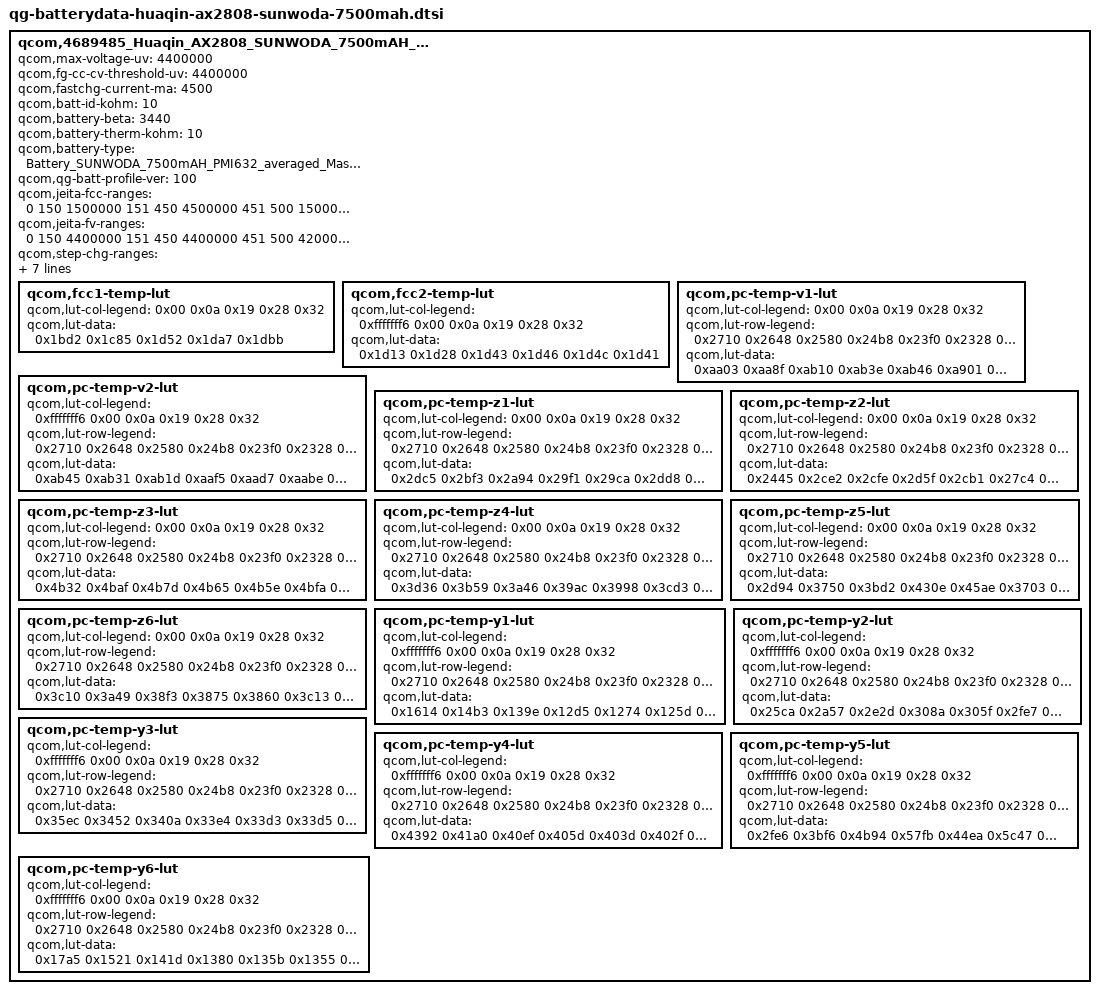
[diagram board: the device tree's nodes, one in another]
qcom,4689485_Huaqin_AX2808_SUNWODA_7500mAH_PMI632 {
	qcom,max-voltage-uv = <4400000>;
	qcom,fg-cc-cv-threshold-uv = <4400000>;
	qcom,fastchg-current-ma = <4500>;
	qcom,batt-id-kohm = <10>;
	qcom,battery-beta = <3440>;
	qcom,battery-therm-kohm = <10>;
	qcom,battery-type = "Battery_SUNWODA_7500mAH_PMI632_averaged_MasterSlave_Jul21th2020";
	qcom,qg-batt-profile-ver = <100>;
	qcom,jeita-fcc-ranges = <0 150 1500000 151 450 4500000 451 500 1500000>;
	qcom,jeita-fv-ranges = <0 150 4400000 151 450 4400000 451 500 4200000>;
	qcom,step-chg-ranges = <3600000 3800000 4500000 3800001 4300000 4500000 4300001 4400000 2500000>;
	qcom,ocv-based-step-chg;
	qcom,jeita-soft-thresholds = <9600 4016>;
	qcom,jeita-hard-thresholds = <22733 8376>;
	qcom,jeita-soft-hys-thresholds = <20318 10563>;
	qcom,jeita-soft-fcc-ua = <4500000 4500000>;
	qcom,jeita-soft-fv-uv = <4400000 4400000>;

	qcom,fcc1-temp-lut {
		qcom,lut-col-legend = <0x00 0x0a 0x19 0x28 0x32>;
		qcom,lut-data = <0x1bd2 0x1c85 0x1d52 0x1da7 0x1dbb>;
	};

	qcom,fcc2-temp-lut {
		qcom,lut-col-legend = <0xfffffff6 0x00 0x0a 0x19 0x28 0x32>;
		qcom,lut-data = <0x1d13 0x1d28 0x1d43 0x1d46 0x1d4c 0x1d41>;
	};

	qcom,pc-temp-v1-lut {
		qcom,lut-col-legend = <0x00 0x0a 0x19 0x28 0x32>;
		qcom,lut-row-legend = <0x2710 0x2648 0x2580 0x24b8 0x23f0 0x2328 0x2260 0x2198 0x20d0 0x2008 0x1f40 0x1e78 0x1db0 0x1ce8 0x1c20 0x1b58 0x1a90 0x19c8 0x1900 0x1838 0x1770 0x16a8 0x15e0 0x1518 0x1450 0x1388 0x12c0 0x11f8 0x1130 0x1068 0xfa0 0xed8 0xe10 0xd48 0xc80 0xbb8 0xaf0 0xa28 0x960 0x898 0x7d0 0x708 0x640 0x578 0x4b0 0x3e8 0x384 0x320 0x2bc 0x258 0x1f4 0x190 0x12c 0xc8 0x64 0x00>;
		qcom,lut-data = <0xaa03 0xaa8f 0xab10 0xab3e 0xab46 0xa901 0xa9ad 0xaa45 0xaa83 0xaa8e 0xa806 0xa8c5 0xa96b 0xa9b6 0xa9c5 0xa715 0xa7d9 0xa88b 0xa8e0 0xa8f2 0xa62c 0xa6ef 0xa7a2 0xa800 0xa815 0xa549 0xa606 0xa6b6 0xa716 0xa730 0xa467 0xa520 0xa5cd 0xa62d 0xa648 0xa389 0xa43c 0xa4e3 0xa541 0xa55e 0xa2b0 0xa35b 0xa3fc 0xa456 0xa475 0xa1dd 0xa27f 0xa316 0xa36d 0xa38f 0xa10e 0xa1aa 0xa234 0xa287 0xa2ac 0xa046 0xa0da 0xa159 0xa1a7 0xa1cc 0x9f85 0xa013 0xa082 0xa0cc 0xa0ed 0x9ec7 0x9f53 0x9fb3 0x9ff9 0xa016 0x9e06 0x9e96 0x9eeb 0x9f2b 0x9f46 0x9d47 0x9dda 0x9e2a 0x9e64 0x9e7e 0x9c9a 0x9d21 0x9d73 0x9da6 0x9dbe 0x9c00 0x9c78 0x9cc3 0x9cf2 0x9d05 0x9b72 0x9be0 0x9c1b 0x9c42 0x9c52 0x9ae9 0x9b49 0x9b81 0x9ba2 0x9bae 0x9a67 0x9aa1 0x9ad4 0x9afb 0x9b08 0x99e4 0x99ee 0x99e1 0x9a1c 0x9a39 0x995b 0x9931 0x98d6 0x98fd 0x9936 0x98d0 0x9851 0x981f 0x982d 0x9865 0x9847 0x978b 0x979d 0x97ba 0x97e3 0x97b8 0x9720 0x9736 0x975f 0x9777 0x9737 0x96d9 0x96e7 0x96ff 0x970a 0x96d9 0x969f 0x96a5 0x96a2 0x969f 0x968e 0x966f 0x9661 0x9648 0x963e 0x9653 0x9645 0x961b 0x95f0 0x95e4 0x9629 0x9619 0x95da 0x959f 0x9592 0x9606 0x95ee 0x959c 0x955a 0x9549 0x95e4 0x95c3 0x9562 0x951e 0x9507 0x95c4 0x9599 0x952f 0x94e5 0x94c8 0x95a4 0x9570 0x9502 0x94b1 0x948e 0x9583 0x9548 0x94d7 0x947d 0x9455 0x9561 0x9523 0x94b0 0x9449 0x9415 0x9534 0x94f6 0x9488 0x9413 0x93d1 0x94e8 0x94ab 0x944b 0x93ce 0x9384 0x9487 0x9442 0x93e7 0x9372 0x932b 0x9421 0x93ce 0x9374 0x9308 0x92c5 0x93ac 0x934e 0x92fc 0x9294 0x9250 0x9329 0x92bd 0x9275 0x9211 0x91c9 0x9292 0x920f 0x91d0 0x9173 0x912b 0x91f1 0x9180 0x9140 0x90e8 0x90a5 0x9186 0x912b 0x90e6 0x9099 0x9057 0x915e 0x910c 0x90d2 0x9083 0x9045 0x913c 0x90fa 0x90c2 0x9072 0x9035 0x9116 0x90ee 0x90ab 0x9061 0x9021 0x90d3 0x90b2 0x9076 0x9028 0x8fe2 0x8ff7 0x8fc7 0x8f80 0x8f21 0x8ecb 0x8e30 0x8e05 0x8dd0 0x8d70 0x8d19 0x8bea 0x8bc3 0x8b9b 0x8b3a 0x8ae4 0x88d5 0x88b3 0x889b 0x8839 0x87e7 0x83e6 0x83e7 0x83fc 0x839c 0x834f 0x7530 0x7530 0x7530 0x7530 0x7530>;
	};

	qcom,pc-temp-v2-lut {
		qcom,lut-col-legend = <0xfffffff6 0x00 0x0a 0x19 0x28 0x32>;
		qcom,lut-row-legend = <0x2710 0x2648 0x2580 0x24b8 0x23f0 0x2328 0x2260 0x2198 0x20d0 0x2008 0x1f40 0x1e78 0x1db0 0x1ce8 0x1c20 0x1b58 0x1a90 0x19c8 0x1900 0x1838 0x1770 0x16a8 0x15e0 0x1518 0x1450 0x1388 0x12c0 0x11f8 0x1130 0x1068 0xfa0 0xed8 0xe10 0xd48 0xc80 0xbb8 0xaf0 0xa28 0x960 0x898 0x7d0 0x708 0x640 0x578 0x4b0 0x3e8 0x384 0x320 0x2bc 0x258 0x1f4 0x190 0x12c 0xc8 0x64 0x00>;
		qcom,lut-data = <0xab45 0xab31 0xab1d 0xaaf5 0xaad7 0xaabe 0xa9a7 0xa9de 0xaa06 0xa9f0 0xa9e1 0xa9d1 0xa828 0xa8a6 0xa8fa 0xa8f3 0xa8ef 0xa8e7 0xa6c9 0xa78b 0xa7fb 0xa800 0xa803 0xa7ff 0xa588 0xa68f 0xa709 0xa716 0xa71d 0xa71b 0xa45e 0xa597 0xa61a 0xa62d 0xa636 0xa636 0xa32d 0xa498 0xa528 0xa543 0xa54d 0xa54e 0xa21a 0xa399 0xa439 0xa459 0xa463 0xa465 0xa183 0xa291 0xa34e 0xa373 0xa37f 0xa380 0xa13c 0xa173 0xa266 0xa28f 0xa29d 0xa29e 0xa0de 0xa087 0xa183 0xa1af 0xa1be 0xa1be 0x9f91 0x9ffb 0xa0a3 0xa0d6 0xa0e4 0xa0e5 0x9d8f 0x9f88 0x9fc9 0xa001 0xa00c 0xa010 0x9c54 0x9ed8 0x9f01 0x9f32 0x9f3c 0x9f42 0x9ba2 0x9dc6 0x9e49 0x9e66 0x9e71 0x9e77 0x9afb 0x9caf 0x9d90 0x9da3 0x9dae 0x9db4 0x9a2e 0x9bcd 0x9cd0 0x9cea 0x9cf4 0x9cf9 0x9955 0x9afb 0x9c0b 0x9c38 0x9c42 0x9c44 0x987d 0x9a21 0x9b30 0x9b85 0x9b93 0x9b95 0x9794 0x993e 0x9a37 0x9ad4 0x9aec 0x9af0 0x96d4 0x9860 0x994d 0x9a17 0x9a36 0x9a3e 0x9661 0x9788 0x9882 0x992d 0x994d 0x9958 0x960a 0x96bb 0x97cb 0x983b 0x985b 0x9865 0x95bc 0x9616 0x972d 0x978b 0x97ab 0x97b5 0x9576 0x958b 0x96a4 0x9706 0x9725 0x9731 0x9537 0x9520 0x9628 0x9692 0x96b0 0x96be 0x94fb 0x94d9 0x95b5 0x9627 0x9647 0x9652 0x94c2 0x94a2 0x954c 0x95c5 0x95e8 0x95ef 0x9489 0x946e 0x94e7 0x956b 0x958f 0x9594 0x944f 0x943f 0x9483 0x9518 0x953a 0x953f 0x9416 0x9411 0x9432 0x94cb 0x94ed 0x94f2 0x93d9 0x93e3 0x93fa 0x9482 0x94a8 0x94ab 0x939b 0x93b5 0x93cd 0x943d 0x9467 0x9469 0x935b 0x9382 0x93a5 0x93fa 0x9422 0x9421 0x9319 0x934b 0x9382 0x93bb 0x93db 0x93d4 0x92d4 0x9310 0x935c 0x937b 0x938d 0x937e 0x928d 0x92ce 0x9332 0x9338 0x932f 0x9315 0x9242 0x9287 0x9302 0x92f4 0x92cb 0x92a1 0x91f4 0x9238 0x92c0 0x92ac 0x9273 0x923f 0x91a3 0x91df 0x925f 0x9261 0x9227 0x91ec 0x9150 0x917f 0x91ef 0x920d 0x91d4 0x9196 0x9101 0x911b 0x9176 0x91a3 0x916e 0x912f 0x90b2 0x90b0 0x90f3 0x9129 0x90f9 0x90bb 0x9063 0x9039 0x906c 0x9096 0x9066 0x902a 0x9010 0x8fbe 0x8fed 0x902e 0x9004 0x8fd0 0x8fb5 0x8f4d 0x8f89 0x9002 0x8fe7 0x8fb0 0x8f7e 0x8f1c 0x8f5f 0x8fed 0x8fd9 0x8fa6 0x8f40 0x8ee7 0x8f38 0x8fda 0x8fc4 0x8f93 0x8ef9 0x8eaf 0x8efe 0x8fb4 0x8fa6 0x8f70 0x8e90 0x8e62 0x8e9b 0x8f62 0x8f47 0x8f0a 0x8de6 0x8dbd 0x8dbb 0x8e41 0x8e20 0x8dcf 0x8ca2 0x8c59 0x8c27 0x8c64 0x8c47 0x8bf3 0x8a90 0x8a19 0x89d2 0x89fd 0x89db 0x8987 0x8789 0x86e4 0x86b3 0x86ac 0x8689 0x8636 0x82ba 0x81e3 0x81cf 0x819e 0x8182 0x8133 0x77e1 0x72c6 0x725b 0x72e2 0x734d 0x7468>;
	};

	qcom,pc-temp-z1-lut {
		qcom,lut-col-legend = <0x00 0x0a 0x19 0x28 0x32>;
		qcom,lut-row-legend = <0x2710 0x2648 0x2580 0x24b8 0x23f0 0x2328 0x2260 0x2198 0x20d0 0x2008 0x1f40 0x1e78 0x1db0 0x1ce8 0x1c20 0x1b58 0x1a90 0x19c8 0x1900 0x1838 0x1770 0x16a8 0x15e0 0x1518 0x1450 0x1388 0x12c0 0x11f8 0x1130 0x1068 0xfa0 0xed8 0xe10 0xd48 0xc80 0xbb8 0xaf0 0xa28 0x960 0x898 0x7d0 0x708 0x640 0x578 0x4b0 0x3e8 0x384 0x320 0x2bc 0x258 0x1f4 0x190 0x12c 0xc8 0x64 0x00>;
		qcom,lut-data = <0x2dc5 0x2bf3 0x2a94 0x29f1 0x29ca 0x2dd8 0x2c0a 0x2a99 0x29fc 0x29d2 0x2de3 0x2c0c 0x2a9c 0x29fb 0x29d4 0x2de2 0x2c08 0x2a9c 0x29fa 0x29d5 0x2dd5 0x2c05 0x2a97 0x29f9 0x29d5 0x2dc9 0x2bff 0x2a92 0x29f7 0x29d4 0x2dc4 0x2bf8 0x2a8e 0x29f5 0x29d3 0x2dc1 0x2bf6 0x2a8b 0x29f3 0x29d3 0x2dbe 0x2bf7 0x2a8a 0x29f2 0x29d3 0x2dba 0x2bf7 0x2a8b 0x29f1 0x29d3 0x2db6 0x2bf0 0x2a8c 0x29f1 0x29d3 0x2db1 0x2be7 0x2a8b 0x29f0 0x29d2 0x2dab 0x2be3 0x2a89 0x29f0 0x29d2 0x2da8 0x2be1 0x2a88 0x29ef 0x29d2 0x2da9 0x2be0 0x2a87 0x29ef 0x29d2 0x2dac 0x2be1 0x2a87 0x29ef 0x29d2 0x2daa 0x2be3 0x2a87 0x29ef 0x29d2 0x2d9d 0x2be5 0x2a88 0x29f0 0x29d3 0x2d91 0x2be6 0x2a8a 0x29f1 0x29d3 0x2d8e 0x2be6 0x2a8c 0x29f2 0x29d4 0x2d88 0x2be6 0x2a8e 0x29f3 0x29d5 0x2d84 0x2be8 0x2a90 0x29f4 0x29d6 0x2d87 0x2be9 0x2a92 0x29f5 0x29d7 0x2d8d 0x2beb 0x2a94 0x29f7 0x29d8 0x2d8f 0x2bec 0x2a97 0x29f9 0x29da 0x2d90 0x2bec 0x2a9a 0x29fb 0x29db 0x2d92 0x2bec 0x2a9b 0x29fd 0x29dd 0x2d93 0x2bed 0x2a9c 0x2a00 0x29e0 0x2d93 0x2bef 0x2a9d 0x2a02 0x29e2 0x2d91 0x2bf1 0x2aa0 0x2a05 0x29e4 0x2d8f 0x2bf1 0x2aa2 0x2a07 0x29e6 0x2d8d 0x2bf1 0x2aa6 0x2a0a 0x29e7 0x2d8d 0x2bf0 0x2aa9 0x2a0c 0x29e8 0x2d8f 0x2bf2 0x2aaa 0x2a0e 0x29e9 0x2d92 0x2bf5 0x2aab 0x2a10 0x29eb 0x2d97 0x2bf9 0x2aac 0x2a12 0x29ed 0x2d9e 0x2bfc 0x2ab1 0x2a13 0x29ee 0x2da7 0x2c00 0x2ab6 0x2a15 0x29f0 0x2db1 0x2c04 0x2ab8 0x2a17 0x29f1 0x2dbb 0x2c08 0x2ab8 0x2a19 0x29f3 0x2dbd 0x2c0b 0x2ab9 0x2a1a 0x29f5 0x2db8 0x2c0f 0x2abb 0x2a1c 0x29f6 0x2dbc 0x2c10 0x2ac0 0x2a1f 0x29f8 0x2dcd 0x2c0f 0x2ac6 0x2a21 0x29f9 0x2dc8 0x2c12 0x2ac9 0x2a24 0x29fb 0x2db1 0x2c17 0x2ad0 0x2a26 0x29fc 0x2db5 0x2c22 0x2ac9 0x2a26 0x29fb 0x2dc8 0x2c1c 0x2ac8 0x2a26 0x29fc 0x2dc8 0x2c10 0x2ac9 0x2a27 0x29fd 0x2db3 0x2c1f 0x2ad2 0x2a2a 0x29fe 0x2dc5 0x2c24 0x2ad3 0x2a2d 0x2a01 0x2dde 0x2c21 0x2ad8 0x2a31 0x2a05 0x2dc3 0x2c39 0x2ae8 0x2a36 0x2a0a 0x2dd3 0x2c3e 0x2aed 0x2a41 0x2a11 0x2dd3 0x2c3e 0x2aed 0x2a41 0x2a11 0x2dd3 0x2c3e 0x2aed 0x2a41 0x2a11>;
	};

	qcom,pc-temp-z2-lut {
		qcom,lut-col-legend = <0x00 0x0a 0x19 0x28 0x32>;
		qcom,lut-row-legend = <0x2710 0x2648 0x2580 0x24b8 0x23f0 0x2328 0x2260 0x2198 0x20d0 0x2008 0x1f40 0x1e78 0x1db0 0x1ce8 0x1c20 0x1b58 0x1a90 0x19c8 0x1900 0x1838 0x1770 0x16a8 0x15e0 0x1518 0x1450 0x1388 0x12c0 0x11f8 0x1130 0x1068 0xfa0 0xed8 0xe10 0xd48 0xc80 0xbb8 0xaf0 0xa28 0x960 0x898 0x7d0 0x708 0x640 0x578 0x4b0 0x3e8 0x384 0x320 0x2bc 0x258 0x1f4 0x190 0x12c 0xc8 0x64 0x00>;
		qcom,lut-data = <0x2445 0x2ce2 0x2cfe 0x2d5f 0x2cb1 0x27c4 0x2c55 0x2cec 0x2d98 0x2d5e 0x2a3c 0x2c13 0x2d49 0x2e08 0x2e4f 0x2acf 0x2be8 0x2d5a 0x2e38 0x2ef0 0x2abc 0x2bbd 0x2d2f 0x2e23 0x2ec4 0x2aa8 0x2b8d 0x2cf8 0x2def 0x2e32 0x2a9e 0x2b60 0x2cba 0x2dbf 0x2dde 0x2a98 0x2b3b 0x2c7d 0x2d87 0x2dbc 0x2a90 0x2b19 0x2c72 0x2d6a 0x2d94 0x2a85 0x2b08 0x2c82 0x2d7a 0x2d1f 0x2a78 0x2b01 0x2c95 0x2d94 0x2c6f 0x2a6a 0x2afd 0x2ca6 0x2d98 0x2c45 0x2a57 0x2b03 0x2cb8 0x2d91 0x2c62 0x2a43 0x2b2b 0x2cc8 0x2d8b 0x2c76 0x2a2d 0x2b57 0x2cdd 0x2d5b 0x2c76 0x2a16 0x2b75 0x2cf1 0x2d1c 0x2c80 0x2a10 0x2b8f 0x2d04 0x2d0b 0x2c9a 0x2a1f 0x2ba5 0x2d16 0x2ce3 0x2cd3 0x2a3c 0x2bb7 0x2d25 0x2cd0 0x2d0e 0x2a5b 0x2bca 0x2d32 0x2cde 0x2d4b 0x2a83 0x2be6 0x2d46 0x2cf9 0x2d7f 0x2aa4 0x2c09 0x2d99 0x2d78 0x2d81 0x2ab9 0x2c18 0x2e07 0x2ed8 0x2d69 0x2ac9 0x2c18 0x2e0d 0x2f76 0x2d5c 0x2adc 0x2c17 0x2dac 0x2e7b 0x2da7 0x2af3 0x2c1b 0x2d69 0x2d58 0x2e29 0x2b0a 0x2c25 0x2d74 0x2da8 0x2e95 0x2b1e 0x2c2e 0x2d90 0x2ef3 0x2f08 0x2b2e 0x2c35 0x2db3 0x2f7a 0x2f2f 0x2b3d 0x2c3c 0x2df0 0x2efe 0x2e8b 0x2b4a 0x2c43 0x2e15 0x2e5f 0x2da6 0x2b56 0x2c4d 0x2deb 0x2e11 0x2d25 0x2b64 0x2c58 0x2da4 0x2dd9 0x2cc2 0x2b73 0x2c64 0x2d97 0x2dcf 0x2ca6 0x2b82 0x2c71 0x2da9 0x2e1e 0x2cdf 0x2b8f 0x2c7a 0x2dc1 0x2e92 0x2d3b 0x2b9c 0x2c82 0x2dd5 0x2f06 0x2da5 0x2bac 0x2c8b 0x2dee 0x2f86 0x2e24 0x2bc8 0x2c9e 0x2e18 0x2fe6 0x2e74 0x2be4 0x2cb9 0x2e68 0x303b 0x2ea9 0x2b89 0x2cc7 0x2e97 0x3069 0x2ec8 0x2a09 0x2ccb 0x2e83 0x3043 0x2eca 0x2970 0x2cd2 0x2e6e 0x2ffc 0x2ec2 0x2821 0x2cfa 0x2e77 0x2fca 0x2ea1 0x2836 0x2df7 0x2ec8 0x2fb1 0x2e96 0x28d1 0x2e47 0x2eec 0x2eec 0x2e75 0x28a9 0x2e48 0x2eb4 0x2e65 0x2e8b 0x28c9 0x2e63 0x2e8c 0x2e84 0x2e74 0x28d5 0x2d4f 0x2e8b 0x2e80 0x2eb8 0x2878 0x2c8d 0x2ed2 0x2f5e 0x2f8c 0x2826 0x2cbf 0x3001 0x2f00 0x2dbf 0x272c 0x2e40 0x2f78 0x2e3f 0x2cbf 0x2671 0x2c7d 0x2f12 0x2d91 0x2c6b 0x25d5 0x2b1f 0x2e94 0x2d43 0x2c04 0x25d5 0x2b1f 0x2e94 0x2d43 0x2c04 0x25d5 0x2b1f 0x2e94 0x2d43 0x2c04>;
	};

	qcom,pc-temp-z3-lut {
		qcom,lut-col-legend = <0x00 0x0a 0x19 0x28 0x32>;
		qcom,lut-row-legend = <0x2710 0x2648 0x2580 0x24b8 0x23f0 0x2328 0x2260 0x2198 0x20d0 0x2008 0x1f40 0x1e78 0x1db0 0x1ce8 0x1c20 0x1b58 0x1a90 0x19c8 0x1900 0x1838 0x1770 0x16a8 0x15e0 0x1518 0x1450 0x1388 0x12c0 0x11f8 0x1130 0x1068 0xfa0 0xed8 0xe10 0xd48 0xc80 0xbb8 0xaf0 0xa28 0x960 0x898 0x7d0 0x708 0x640 0x578 0x4b0 0x3e8 0x384 0x320 0x2bc 0x258 0x1f4 0x190 0x12c 0xc8 0x64 0x00>;
		qcom,lut-data = <0x4b32 0x4baf 0x4b7d 0x4b65 0x4b5e 0x4bfa 0x4bff 0x4ba6 0x4b7d 0x4b6b 0x4c8b 0x4c24 0x4bbf 0x4b8a 0x4b77 0x4cba 0x4c3c 0x4bcc 0x4b92 0x4b81 0x4cc9 0x4c47 0x4bd4 0x4b98 0x4b87 0x4ccf 0x4c4b 0x4bd8 0x4b9c 0x4b8b 0x4cd0 0x4c4e 0x4bd6 0x4b9d 0x4b8c 0x4ccf 0x4c4e 0x4bd2 0x4b9d 0x4b8c 0x4ccd 0x4c4e 0x4bcf 0x4b9d 0x4b8c 0x4cc7 0x4c4e 0x4bcc 0x4b9b 0x4b88 0x4cc0 0x4c49 0x4bc8 0x4b97 0x4b7f 0x4cbf 0x4c41 0x4bc3 0x4b92 0x4b7b 0x4cc1 0x4c39 0x4bbe 0x4b8c 0x4b79 0x4cc4 0x4c32 0x4bba 0x4b87 0x4b78 0x4ccb 0x4c2b 0x4bb6 0x4b82 0x4b74 0x4cd7 0x4c25 0x4bb2 0x4b7d 0x4b70 0x4cdb 0x4c20 0x4bb0 0x4b7b 0x4b6e 0x4cd1 0x4c1e 0x4baf 0x4b77 0x4b6d 0x4cc3 0x4c1d 0x4bad 0x4b75 0x4b6d 0x4cbb 0x4c1d 0x4bac 0x4b75 0x4b6b 0x4cb6 0x4c1e 0x4bab 0x4b75 0x4b6a 0x4cb3 0x4c21 0x4bb3 0x4b79 0x4b6a 0x4cb4 0x4c24 0x4bc1 0x4b84 0x4b6d 0x4cb6 0x4c29 0x4bc3 0x4b88 0x4b6f 0x4cb7 0x4c2c 0x4bbc 0x4b7e 0x4b69 0x4cb7 0x4c2b 0x4bb4 0x4b71 0x4b61 0x4cb7 0x4c26 0x4bad 0x4b71 0x4b66 0x4cb6 0x4c22 0x4ba7 0x4b76 0x4b7c 0x4cb1 0x4c1d 0x4ba7 0x4b7c 0x4b86 0x4cab 0x4c1a 0x4bb3 0x4b89 0x4b85 0x4ca5 0x4c19 0x4bbd 0x4b94 0x4b82 0x4c9d 0x4c19 0x4bc0 0x4b93 0x4b7e 0x4c97 0x4c18 0x4bc2 0x4b8d 0x4b79 0x4c91 0x4c19 0x4bc2 0x4b88 0x4b74 0x4c8c 0x4c18 0x4bbe 0x4b83 0x4b70 0x4c86 0x4c17 0x4bb9 0x4b80 0x4b6d 0x4c80 0x4c14 0x4bb4 0x4b7f 0x4b6d 0x4c7b 0x4c10 0x4bb0 0x4b7e 0x4b6d 0x4c77 0x4c0d 0x4bae 0x4b7d 0x4b6d 0x4c73 0x4c0a 0x4bad 0x4b7d 0x4b6b 0x4c52 0x4c06 0x4bab 0x4b7d 0x4b6a 0x4bec 0x4c03 0x4ba9 0x4b7c 0x4b6a 0x4bb7 0x4bfe 0x4ba6 0x4b7a 0x4b6b 0x4b44 0x4bf6 0x4ba3 0x4b78 0x4b6c 0x4b3d 0x4bdb 0x4b9a 0x4b76 0x4b6a 0x4b3c 0x4bc9 0x4b96 0x4b6d 0x4b66 0x4b3c 0x4bc8 0x4b92 0x4b6e 0x4b62 0x4b3c 0x4ba9 0x4b8d 0x4b6c 0x4b60 0x4b3c 0x4b3b 0x4b8c 0x4b67 0x4b5d 0x4b3d 0x4b3c 0x4b87 0x4b62 0x4b5c 0x4b3d 0x4b3c 0x4b7d 0x4b65 0x4b69 0x4b3f 0x4b3b 0x4b7b 0x4b68 0x4b6c 0x4b40 0x4b3b 0x4b70 0x4b6b 0x4b6c 0x4b43 0x4b3c 0x4b71 0x4b6b 0x4b6d 0x4b43 0x4b3c 0x4b71 0x4b6b 0x4b6d 0x4b43 0x4b3c 0x4b71 0x4b6b 0x4b6d>;
	};

	qcom,pc-temp-z4-lut {
		qcom,lut-col-legend = <0x00 0x0a 0x19 0x28 0x32>;
		qcom,lut-row-legend = <0x2710 0x2648 0x2580 0x24b8 0x23f0 0x2328 0x2260 0x2198 0x20d0 0x2008 0x1f40 0x1e78 0x1db0 0x1ce8 0x1c20 0x1b58 0x1a90 0x19c8 0x1900 0x1838 0x1770 0x16a8 0x15e0 0x1518 0x1450 0x1388 0x12c0 0x11f8 0x1130 0x1068 0xfa0 0xed8 0xe10 0xd48 0xc80 0xbb8 0xaf0 0xa28 0x960 0x898 0x7d0 0x708 0x640 0x578 0x4b0 0x3e8 0x384 0x320 0x2bc 0x258 0x1f4 0x190 0x12c 0xc8 0x64 0x00>;
		qcom,lut-data = <0x3d36 0x3b59 0x3a46 0x39ac 0x3998 0x3cd3 0x3b62 0x3a5c 0x39dd 0x39ab 0x3c74 0x3b44 0x3a47 0x39d1 0x39a5 0x3c18 0x3aec 0x3a2b 0x39c1 0x399c 0x3bbd 0x3aa0 0x3a04 0x39af 0x3990 0x3b6b 0x3a68 0x39df 0x399a 0x3980 0x3b28 0x3a38 0x39c7 0x3989 0x3972 0x3aef 0x3a11 0x39b3 0x3979 0x3963 0x3ac0 0x39ef 0x39a0 0x396c 0x3959 0x3a9a 0x39d5 0x398b 0x3962 0x3955 0x3a79 0x39c2 0x397c 0x3959 0x3952 0x3a59 0x39b1 0x3975 0x3953 0x394f 0x3a3a 0x39a2 0x3970 0x3950 0x3949 0x3a1d 0x3992 0x396c 0x394d 0x3943 0x3a03 0x3989 0x3967 0x394a 0x3940 0x39ec 0x3988 0x3962 0x3947 0x393c 0x39dc 0x3988 0x395c 0x3944 0x3938 0x39d2 0x3987 0x3957 0x3940 0x3932 0x39c9 0x397b 0x3954 0x393d 0x392e 0x39bb 0x3970 0x3952 0x393b 0x392e 0x39a7 0x3973 0x3951 0x393a 0x392e 0x399c 0x397e 0x396b 0x3949 0x393a 0x399c 0x398e 0x399c 0x3980 0x396e 0x399e 0x39bb 0x39b4 0x399e 0x398d 0x39a3 0x39e4 0x39c2 0x39a2 0x398f 0x39b4 0x39e6 0x39c8 0x39a4 0x3990 0x39c6 0x39df 0x39c4 0x399f 0x3987 0x39cb 0x39d7 0x39bb 0x398e 0x3964 0x39cd 0x39cc 0x39ae 0x397b 0x394c 0x39cd 0x39be 0x3997 0x3962 0x3943 0x39c9 0x39b2 0x3983 0x394d 0x393d 0x39bf 0x39a7 0x3976 0x3947 0x3939 0x39b7 0x399d 0x396c 0x3943 0x3936 0x39af 0x3995 0x396a 0x3942 0x3935 0x39a7 0x398e 0x396a 0x3943 0x3936 0x399f 0x3989 0x396a 0x3944 0x3938 0x3997 0x3984 0x396a 0x3946 0x393b 0x3990 0x3981 0x396a 0x394a 0x3942 0x398a 0x3982 0x396b 0x394f 0x3947 0x3985 0x3985 0x3973 0x3955 0x394b 0x399d 0x3985 0x3978 0x3959 0x394d 0x39fc 0x397c 0x3972 0x3956 0x394a 0x3a26 0x3972 0x3968 0x3951 0x3945 0x3a82 0x396b 0x3963 0x3951 0x3946 0x3a35 0x3954 0x3954 0x394a 0x3943 0x3a27 0x394b 0x3941 0x393f 0x3937 0x3a23 0x3946 0x393a 0x3936 0x3932 0x3a1d 0x395a 0x3933 0x3929 0x3926 0x3a1a 0x39ce 0x3929 0x3921 0x391c 0x3a15 0x39ca 0x392e 0x3928 0x391e 0x3a16 0x39d2 0x394b 0x393b 0x3924 0x3a25 0x39da 0x3952 0x3939 0x3924 0x3a2c 0x39de 0x395e 0x3936 0x3924 0x3a3c 0x39e2 0x395f 0x3937 0x3922 0x3a3c 0x39e2 0x395f 0x3937 0x3922 0x3a3c 0x39e2 0x395f 0x3937 0x3922>;
	};

	qcom,pc-temp-z5-lut {
		qcom,lut-col-legend = <0x00 0x0a 0x19 0x28 0x32>;
		qcom,lut-row-legend = <0x2710 0x2648 0x2580 0x24b8 0x23f0 0x2328 0x2260 0x2198 0x20d0 0x2008 0x1f40 0x1e78 0x1db0 0x1ce8 0x1c20 0x1b58 0x1a90 0x19c8 0x1900 0x1838 0x1770 0x16a8 0x15e0 0x1518 0x1450 0x1388 0x12c0 0x11f8 0x1130 0x1068 0xfa0 0xed8 0xe10 0xd48 0xc80 0xbb8 0xaf0 0xa28 0x960 0x898 0x7d0 0x708 0x640 0x578 0x4b0 0x3e8 0x384 0x320 0x2bc 0x258 0x1f4 0x190 0x12c 0xc8 0x64 0x00>;
		qcom,lut-data = <0x2d94 0x3750 0x3bd2 0x430e 0x45ae 0x3703 0x40be 0x454c 0x4c46 0x4d7d 0x3e34 0x46d4 0x4bcb 0x51d0 0x5554 0x41f1 0x4b70 0x506d 0x558c 0x5c8e 0x43e2 0x4f74 0x543a 0x587f 0x60eb 0x4570 0x52ce 0x5656 0x5b1a 0x643a 0x474c 0x5610 0x56ee 0x5d79 0x674f 0x492e 0x5a7a 0x574d 0x5ffe 0x6b32 0x4aa8 0x6035 0x58cb 0x62c3 0x6db2 0x4b98 0x6498 0x5e1c 0x6693 0x6a95 0x4c78 0x66c7 0x624f 0x6a30 0x642b 0x4e0d 0x68af 0x6347 0x6a5f 0x62f3 0x5113 0x6c11 0x63cb 0x6786 0x6689 0x5571 0x7242 0x64db 0x64ad 0x6934 0x5e47 0x7794 0x66d2 0x631b 0x67d1 0x6af7 0x79cc 0x6986 0x6294 0x6588 0x70f7 0x7b70 0x6e39 0x62c4 0x665b 0x714a 0x7ef9 0x74e4 0x62f2 0x6e20 0x716a 0x88ab 0x7b28 0x644e 0x75e7 0x74d3 0x96ba 0x80d5 0x68fc 0x7ac3 0x8195 0xab7b 0x89b5 0x717a 0x7ea0 0x92e5 0xc7a9 0xb506 0x849f 0x80ca 0xa921 0xda9d 0xf179 0xaabe 0x8261 0xc420 0xe6dd 0xf6a1 0xba86 0x825b 0xda05 0xee3c 0xc5ae 0x912e 0x6b3c 0xee0a 0xe788 0x966b 0x5f33 0x4d9d 0xfb07 0xccc0 0x7d89 0x55cf 0x4db2 0xf9dc 0xb65f 0x6bde 0x5288 0x5cc7 0xf08a 0xa880 0x69e8 0x528e 0x6a55 0xe554 0x9edb 0x72d1 0x6633 0x73a0 0xd813 0x9e1a 0x7fb4 0x7f29 0x7b3c 0xca35 0xa20e 0x939c 0x8a52 0x80c3 0xc218 0xa7d9 0xab42 0x91c0 0x853f 0xbd35 0xb31f 0xb73e 0x9841 0x8924 0xb965 0xc15b 0xbeef 0x9f76 0x8da2 0xb595 0xc78a 0xc240 0xa3e9 0x9099 0xb216 0xca7f 0xbe4c 0xa386 0x9069 0xb10d 0xcbd8 0xb5a2 0xa18e 0x8f32 0xb94e 0xca8f 0xacdb 0x9d80 0x8c05 0xc419 0xc742 0xa288 0x8ef4 0x7b3d 0xb8d2 0xc3aa 0x99dd 0x8104 0x6d24 0x8501 0xbdc7 0x94cf 0x7c5e 0x6d1a 0x68d8 0xb770 0x903d 0x7900 0x6da0 0x33bc 0xb0de 0x8870 0x7011 0x6a6e 0x32c4 0xaddb 0x8ab5 0x6f44 0x6701 0x325b 0x944b 0x98a2 0x67ea 0x6572 0x3224 0x91fa 0x8f0d 0x6ea0 0x607e 0x31d0 0x6523 0x8372 0x7cab 0x691f 0x31bc 0x31ff 0x91ae 0x7cc4 0x7b9a 0x31e0 0x3234 0x7f3b 0x682a 0x6d47 0x3203 0x3299 0x5548 0x4e89 0x66be 0x31a2 0x3203 0x4c84 0x4e01 0x66e2 0x3127 0x318c 0x4327 0x4e9c 0x62ac 0x305d 0x30f5 0x415b 0x4ba9 0x6045 0x305d 0x30f5 0x415b 0x4ba9 0x6045 0x305d 0x30f5 0x415b 0x4ba9 0x6045>;
	};

	qcom,pc-temp-z6-lut {
		qcom,lut-col-legend = <0x00 0x0a 0x19 0x28 0x32>;
		qcom,lut-row-legend = <0x2710 0x2648 0x2580 0x24b8 0x23f0 0x2328 0x2260 0x2198 0x20d0 0x2008 0x1f40 0x1e78 0x1db0 0x1ce8 0x1c20 0x1b58 0x1a90 0x19c8 0x1900 0x1838 0x1770 0x16a8 0x15e0 0x1518 0x1450 0x1388 0x12c0 0x11f8 0x1130 0x1068 0xfa0 0xed8 0xe10 0xd48 0xc80 0xbb8 0xaf0 0xa28 0x960 0x898 0x7d0 0x708 0x640 0x578 0x4b0 0x3e8 0x384 0x320 0x2bc 0x258 0x1f4 0x190 0x12c 0xc8 0x64 0x00>;
		qcom,lut-data = <0x3c10 0x3a49 0x38f3 0x3875 0x3860 0x3c13 0x3a66 0x390c 0x3895 0x3872 0x3c12 0x3a5c 0x390e 0x3896 0x3876 0x3c09 0x3a37 0x390c 0x3897 0x3878 0x3bd7 0x3a14 0x38fe 0x3894 0x3876 0x3b98 0x39f5 0x38ec 0x388c 0x3871 0x3b6c 0x39d8 0x38df 0x3885 0x386c 0x3b46 0x39c0 0x38d4 0x387e 0x3867 0x3b25 0x39ac 0x38c8 0x3878 0x3862 0x3b08 0x399a 0x38bd 0x3872 0x385d 0x3aef 0x398a 0x38b4 0x386c 0x3857 0x3ad9 0x397b 0x38ae 0x3866 0x3853 0x3ac6 0x396e 0x38a9 0x3862 0x3850 0x3ab6 0x3961 0x38a4 0x385d 0x384c 0x3aaa 0x3958 0x38a0 0x3859 0x3849 0x3aa1 0x3954 0x389c 0x3855 0x3845 0x3a96 0x3952 0x3898 0x3852 0x3842 0x3a89 0x394e 0x3895 0x384e 0x383f 0x3a7b 0x3949 0x3894 0x384c 0x383d 0x3a6e 0x3946 0x3893 0x384b 0x383c 0x3a61 0x3948 0x3892 0x384b 0x383b 0x3a5b 0x394f 0x38a3 0x3853 0x3840 0x3a5c 0x395a 0x38c0 0x3872 0x3859 0x3a5e 0x3970 0x38c9 0x3881 0x3867 0x3a62 0x3984 0x38cc 0x387e 0x3865 0x3a6c 0x3985 0x38cc 0x3879 0x3863 0x3a75 0x3980 0x38c9 0x3875 0x3860 0x3a76 0x397b 0x38c2 0x3872 0x385e 0x3a75 0x3975 0x38be 0x386f 0x385b 0x3a74 0x396f 0x38ba 0x386c 0x3857 0x3a6f 0x396a 0x38b8 0x3868 0x3853 0x3a68 0x3966 0x38b5 0x3865 0x384f 0x3a63 0x3963 0x38b3 0x3861 0x384b 0x3a5e 0x3960 0x38b1 0x385e 0x3848 0x3a5a 0x395e 0x38b0 0x385c 0x3846 0x3a56 0x395c 0x38ae 0x385a 0x3845 0x3a52 0x395b 0x38ac 0x385b 0x3846 0x3a51 0x395a 0x38ab 0x385c 0x3849 0x3a50 0x395b 0x38ab 0x385e 0x384b 0x3a4f 0x395e 0x38af 0x3861 0x384c 0x3a4e 0x395f 0x38b1 0x3863 0x384c 0x3a4a 0x395c 0x38af 0x3861 0x384b 0x3a48 0x3959 0x38ab 0x385e 0x384a 0x3a3f 0x3957 0x38a9 0x385e 0x384b 0x3a23 0x3947 0x38a0 0x385b 0x3849 0x3a20 0x393e 0x3898 0x3851 0x3842 0x3a1e 0x393c 0x3893 0x384d 0x383e 0x3a1d 0x3936 0x388d 0x3848 0x3837 0x3a1e 0x3933 0x388a 0x3841 0x3831 0x3a20 0x3935 0x388a 0x3842 0x3832 0x3a27 0x393d 0x3894 0x384c 0x383d 0x3a35 0x3945 0x3898 0x384f 0x383f 0x3a43 0x394e 0x389b 0x3851 0x3840 0x3a5a 0x395b 0x38a0 0x3853 0x3842 0x3a5a 0x395b 0x38a0 0x3853 0x3842 0x3a5a 0x395b 0x38a0 0x3853 0x3842>;
	};

	qcom,pc-temp-y1-lut {
		qcom,lut-col-legend = <0xfffffff6 0x00 0x0a 0x19 0x28 0x32>;
		qcom,lut-row-legend = <0x2710 0x2648 0x2580 0x24b8 0x23f0 0x2328 0x2260 0x2198 0x20d0 0x2008 0x1f40 0x1e78 0x1db0 0x1ce8 0x1c20 0x1b58 0x1a90 0x19c8 0x1900 0x1838 0x1770 0x16a8 0x15e0 0x1518 0x1450 0x1388 0x12c0 0x11f8 0x1130 0x1068 0xfa0 0xed8 0xe10 0xd48 0xc80 0xbb8 0xaf0 0xa28 0x960 0x898 0x7d0 0x708 0x640 0x578 0x4b0 0x3e8 0x384 0x320 0x2bc 0x258 0x1f4 0x190 0x12c 0xc8 0x64 0x00>;
		qcom,lut-data = <0x1614 0x14b3 0x139e 0x12d5 0x1274 0x125d 0x1614 0x14ad 0x139d 0x12d4 0x1274 0x125d 0x1613 0x14a5 0x139b 0x12d3 0x1274 0x125c 0x1611 0x149c 0x1399 0x12d1 0x1273 0x125c 0x160e 0x1494 0x1398 0x12d0 0x1273 0x125b 0x160b 0x148e 0x1397 0x12cf 0x1272 0x125b 0x1607 0x148a 0x1396 0x12ce 0x1271 0x125b 0x1603 0x1487 0x1395 0x12cd 0x1270 0x125a 0x1602 0x1487 0x1395 0x12cc 0x126f 0x125a 0x15fe 0x1489 0x1398 0x12cb 0x126f 0x125a 0x15fb 0x148b 0x139a 0x12ca 0x126e 0x1259 0x15fc 0x148d 0x139a 0x12cb 0x126d 0x1259 0x15ff 0x148f 0x1399 0x12cc 0x126c 0x1258 0x15ff 0x1493 0x139a 0x12cc 0x126c 0x1258 0x15f6 0x1497 0x139f 0x12ca 0x126c 0x1258 0x15ef 0x1499 0x13a2 0x12c8 0x126c 0x1258 0x15f6 0x1497 0x139f 0x12ca 0x126c 0x1259 0x1605 0x1494 0x139b 0x12cb 0x126c 0x1259 0x160a 0x1494 0x139b 0x12cd 0x126d 0x1259 0x1608 0x1496 0x139c 0x12ce 0x126d 0x1259 0x1606 0x1497 0x139d 0x12ce 0x126e 0x125a 0x1608 0x1494 0x139f 0x12ce 0x126e 0x125a 0x160c 0x148f 0x13a0 0x12cf 0x126e 0x125a 0x160c 0x148e 0x139f 0x12d0 0x126e 0x125b 0x1608 0x1490 0x139e 0x12d3 0x1270 0x125b 0x1603 0x1493 0x139d 0x12d5 0x1272 0x125c 0x1601 0x1493 0x139b 0x12d7 0x1273 0x125d 0x15fd 0x1493 0x1399 0x12d9 0x1273 0x125e 0x15f8 0x1493 0x1399 0x12da 0x1275 0x125f 0x15f1 0x1495 0x1399 0x12dd 0x1277 0x1260 0x15ec 0x1496 0x1399 0x12e0 0x1279 0x1261 0x15eb 0x1494 0x139b 0x12e0 0x127a 0x1262 0x15ea 0x1491 0x139f 0x12e1 0x127c 0x1263 0x15e9 0x148f 0x13a1 0x12e2 0x127e 0x1265 0x15e8 0x1490 0x13a0 0x12e4 0x127f 0x1266 0x15e6 0x1491 0x13a0 0x12e5 0x1281 0x1267 0x15e5 0x1493 0x139f 0x12e6 0x1282 0x1269 0x15e4 0x1496 0x139f 0x12e5 0x1283 0x126a 0x15e5 0x1496 0x13a0 0x12e6 0x1284 0x126b 0x15fb 0x1492 0x13a5 0x12e9 0x1285 0x126b 0x1612 0x148f 0x13a9 0x12ec 0x1286 0x126c 0x1606 0x148f 0x13aa 0x12eb 0x1287 0x126d 0x15e5 0x148f 0x13ab 0x12ea 0x1289 0x126e 0x15e5 0x149a 0x13ad 0x12ef 0x128a 0x126f 0x15e7 0x14a5 0x13ac 0x12f0 0x128b 0x126f 0x15eb 0x14a6 0x13b0 0x12f3 0x128b 0x1270 0x1616 0x14a9 0x13ad 0x12ef 0x128c 0x1270 0x161d 0x14aa 0x13aa 0x12f2 0x128d 0x1270 0x15fe 0x14aa 0x13a7 0x12f4 0x128d 0x1271 0x1612 0x14b8 0x13b0 0x12f2 0x128e 0x1272 0x160f 0x14bc 0x13b1 0x12f5 0x128e 0x1272 0x1634 0x14c5 0x13b4 0x12ff 0x1290 0x1275 0x1654 0x14d0 0x13c1 0x1301 0x1296 0x1278 0x166f 0x14e4 0x13de 0x1313 0x129b 0x127c 0x166f 0x14e4 0x13de 0x1313 0x129b 0x127c 0x166f 0x14e4 0x13de 0x1313 0x129b 0x127c>;
	};

	qcom,pc-temp-y2-lut {
		qcom,lut-col-legend = <0xfffffff6 0x00 0x0a 0x19 0x28 0x32>;
		qcom,lut-row-legend = <0x2710 0x2648 0x2580 0x24b8 0x23f0 0x2328 0x2260 0x2198 0x20d0 0x2008 0x1f40 0x1e78 0x1db0 0x1ce8 0x1c20 0x1b58 0x1a90 0x19c8 0x1900 0x1838 0x1770 0x16a8 0x15e0 0x1518 0x1450 0x1388 0x12c0 0x11f8 0x1130 0x1068 0xfa0 0xed8 0xe10 0xd48 0xc80 0xbb8 0xaf0 0xa28 0x960 0x898 0x7d0 0x708 0x640 0x578 0x4b0 0x3e8 0x384 0x320 0x2bc 0x258 0x1f4 0x190 0x12c 0xc8 0x64 0x00>;
		qcom,lut-data = <0x25ca 0x2a57 0x2e2d 0x308a 0x305f 0x2fe7 0x25cb 0x2ad5 0x2e11 0x304b 0x3018 0x2fc4 0x25cc 0x2b3b 0x2df6 0x300f 0x2fd0 0x2f9e 0x25cc 0x2b87 0x2dda 0x2fd7 0x2f8f 0x2f7a 0x25cd 0x2bb7 0x2dbe 0x2fa3 0x2f5d 0x2f58 0x25cd 0x2bc8 0x2da2 0x2f73 0x2f42 0x2f3c 0x25cc 0x2bab 0x2d80 0x2f40 0x2f34 0x2f18 0x25cc 0x2b7d 0x2d62 0x2f16 0x2f2a 0x2ee8 0x25cc 0x2b90 0x2d5d 0x2f10 0x2f2a 0x2ec2 0x25cc 0x2c41 0x2d63 0x2f16 0x2f2e 0x2e9e 0x25cd 0x2cbe 0x2d6d 0x2f1c 0x2f2b 0x2e86 0x25cb 0x2c8c 0x2d82 0x2f24 0x2f1a 0x2e93 0x25c9 0x2c36 0x2da9 0x2f32 0x2f09 0x2eb3 0x25c8 0x2c3a 0x2ddd 0x2f44 0x2f11 0x2eba 0x25c8 0x2cd5 0x2e31 0x2f6b 0x2f3c 0x2ec4 0x25c8 0x2d4e 0x2e7b 0x2f9f 0x2f60 0x2ecc 0x25c7 0x2d5b 0x2eb2 0x2fef 0x2f96 0x2ed7 0x25c7 0x2d61 0x2eda 0x3051 0x2ffc 0x2ef8 0x25c6 0x2d61 0x2edd 0x309b 0x3085 0x2f57 0x25c6 0x2d5b 0x2ec7 0x30df 0x3179 0x3089 0x25c5 0x2d4e 0x2eb9 0x3100 0x3201 0x3152 0x25c5 0x2b37 0x2eca 0x30e0 0x3186 0x3118 0x25c4 0x2750 0x2eef 0x30ae 0x30c9 0x30b8 0x25c4 0x2622 0x2f18 0x30ab 0x30a7 0x30aa 0x25c3 0x2603 0x2f50 0x30d6 0x30b3 0x30d1 0x25c3 0x25f3 0x2f7a 0x30fe 0x30c6 0x30fb 0x25c3 0x25ea 0x2f90 0x3119 0x30ee 0x3131 0x25c3 0x25e4 0x2fa1 0x3138 0x312c 0x317a 0x25c2 0x25de 0x2f7d 0x3155 0x316b 0x31ab 0x25c2 0x25d9 0x2e7c 0x317b 0x31b2 0x31e2 0x25c2 0x25d5 0x2db4 0x31a0 0x31f2 0x3205 0x25c2 0x25d1 0x2e14 0x31c4 0x322d 0x3218 0x25c2 0x25ce 0x2ed3 0x31e3 0x325f 0x3230 0x25c2 0x25cb 0x2eeb 0x31db 0x3277 0x3237 0x25c2 0x25c8 0x2e98 0x318a 0x3289 0x3239 0x25c2 0x25c7 0x2e32 0x3146 0x3289 0x323b 0x25c2 0x25c5 0x2ddb 0x313c 0x322e 0x3234 0x25c2 0x25c4 0x2d6f 0x3141 0x319f 0x3222 0x25c2 0x25c3 0x2c52 0x3140 0x316f 0x3216 0x25c1 0x25c2 0x2915 0x3128 0x3174 0x31fb 0x25c1 0x25c2 0x26b1 0x310a 0x3182 0x31ec 0x25c1 0x25c1 0x263c 0x30e3 0x31b5 0x31b2 0x25c1 0x25c0 0x2604 0x30ab 0x31db 0x3162 0x25c0 0x25c0 0x25eb 0x3047 0x3171 0x3175 0x25c0 0x25bf 0x25de 0x2fb3 0x312f 0x30fd 0x25bf 0x25bf 0x25dd 0x2fb6 0x3117 0x306f 0x25bf 0x25bf 0x25db 0x2fc8 0x30aa 0x2fe1 0x25bf 0x25be 0x25d8 0x2fae 0x303c 0x2fc8 0x25be 0x25be 0x25d4 0x2fa7 0x30e7 0x3016 0x25bc 0x25be 0x25d0 0x2f74 0x3089 0x3020 0x25ba 0x25bd 0x25cc 0x2ee3 0x2ff3 0x2f6a 0x25ba 0x25bc 0x25c8 0x2e43 0x3005 0x2ef6 0x25b8 0x25b9 0x25c3 0x2d99 0x2f82 0x2e2a 0x25b6 0x25b8 0x25bf 0x2cfb 0x2eac 0x2de6 0x25b6 0x25b8 0x25bf 0x2cfb 0x2eac 0x2de6 0x25b6 0x25b8 0x25bf 0x2cfb 0x2eac 0x2de6>;
	};

	qcom,pc-temp-y3-lut {
		qcom,lut-col-legend = <0xfffffff6 0x00 0x0a 0x19 0x28 0x32>;
		qcom,lut-row-legend = <0x2710 0x2648 0x2580 0x24b8 0x23f0 0x2328 0x2260 0x2198 0x20d0 0x2008 0x1f40 0x1e78 0x1db0 0x1ce8 0x1c20 0x1b58 0x1a90 0x19c8 0x1900 0x1838 0x1770 0x16a8 0x15e0 0x1518 0x1450 0x1388 0x12c0 0x11f8 0x1130 0x1068 0xfa0 0xed8 0xe10 0xd48 0xc80 0xbb8 0xaf0 0xa28 0x960 0x898 0x7d0 0x708 0x640 0x578 0x4b0 0x3e8 0x384 0x320 0x2bc 0x258 0x1f4 0x190 0x12c 0xc8 0x64 0x00>;
		qcom,lut-data = <0x35ec 0x3452 0x340a 0x33e4 0x33d3 0x33d5 0x35d4 0x345b 0x340d 0x33e4 0x33d4 0x33d4 0x35bd 0x3463 0x3410 0x33e4 0x33d5 0x33d4 0x35a5 0x3468 0x3413 0x33e4 0x33d5 0x33d4 0x358d 0x346c 0x3415 0x33e5 0x33d6 0x33d5 0x3575 0x346d 0x3417 0x33e5 0x33d6 0x33d5 0x3557 0x346c 0x3419 0x33e5 0x33d7 0x33d5 0x353c 0x3469 0x341a 0x33e6 0x33d7 0x33d6 0x3539 0x3463 0x341a 0x33e6 0x33d8 0x33d6 0x354d 0x3454 0x341b 0x33e6 0x33da 0x33d6 0x355c 0x344a 0x341b 0x33e6 0x33dc 0x33d6 0x3544 0x344c 0x341a 0x33e8 0x33dc 0x33d7 0x351a 0x3450 0x3418 0x33ea 0x33db 0x33d9 0x350f 0x3450 0x3416 0x33ea 0x33db 0x33da 0x3514 0x344e 0x3415 0x33e9 0x33da 0x33d9 0x351b 0x344a 0x3414 0x33e9 0x33da 0x33d9 0x3522 0x3444 0x3412 0x33ea 0x33db 0x33d8 0x3529 0x343c 0x3410 0x33eb 0x33dd 0x33d8 0x3529 0x3434 0x340d 0x33eb 0x33de 0x33d9 0x3521 0x342b 0x3408 0x33ec 0x33e0 0x33db 0x351a 0x3425 0x3403 0x33ec 0x33e1 0x33dd 0x3523 0x3424 0x3400 0x33e9 0x33de 0x33da 0x353d 0x3424 0x33fd 0x33e4 0x33d9 0x33d5 0x3558 0x3421 0x33fb 0x33e2 0x33d7 0x33d3 0x3577 0x3413 0x33fa 0x33e2 0x33d5 0x33d3 0x3598 0x3409 0x33f9 0x33e1 0x33d5 0x33d3 0x35b8 0x340e 0x33f7 0x33e1 0x33d5 0x33d3 0x35da 0x341d 0x33f6 0x33e1 0x33d6 0x33d3 0x35fd 0x342c 0x33f3 0x33e1 0x33d6 0x33d3 0x3620 0x343e 0x33ee 0x33e2 0x33d6 0x33d3 0x3645 0x3453 0x33ea 0x33e2 0x33d6 0x33d4 0x3669 0x346e 0x33ec 0x33e2 0x33d6 0x33d4 0x368e 0x3491 0x33f0 0x33e1 0x33d7 0x33d5 0x36b2 0x34b8 0x33f3 0x33e1 0x33d7 0x33d5 0x36d8 0x34e4 0x33f7 0x33e0 0x33d7 0x33d5 0x36fc 0x3516 0x33fc 0x33e0 0x33d7 0x33d5 0x371e 0x354f 0x33ff 0x33e0 0x33d7 0x33d5 0x373e 0x358f 0x3403 0x33e0 0x33d6 0x33d4 0x375b 0x35d2 0x3408 0x33e0 0x33d6 0x33d3 0x3775 0x3619 0x340d 0x33e0 0x33d6 0x33d3 0x3790 0x3661 0x3413 0x33e0 0x33d6 0x33d3 0x37af 0x36a6 0x341e 0x33e1 0x33d6 0x33d3 0x37d4 0x36e8 0x342e 0x33e2 0x33d6 0x33d3 0x3802 0x3724 0x3442 0x33e3 0x33d5 0x33d3 0x3840 0x375b 0x345e 0x33e5 0x33d4 0x33d3 0x387f 0x3760 0x3464 0x33e7 0x33d9 0x33d4 0x3884 0x3767 0x3475 0x33e8 0x33d8 0x33d7 0x38ee 0x37a6 0x3493 0x33eb 0x33d8 0x33d8 0x3968 0x37f0 0x34b6 0x33ee 0x33de 0x33db 0x3a64 0x3848 0x34e3 0x33f4 0x33df 0x33dc 0x3c9e 0x38b5 0x3512 0x33ef 0x33db 0x33d7 0x4071 0x39a0 0x3563 0x33f2 0x33dd 0x33d8 0x4895 0x3c37 0x360d 0x33f9 0x33de 0x33d9 0x5b1f 0x423f 0x3769 0x3401 0x33e1 0x33dd 0x5b1f 0x423f 0x3769 0x3401 0x33e1 0x33dd 0x5b1f 0x423f 0x3769 0x3401 0x33e1 0x33dd>;
	};

	qcom,pc-temp-y4-lut {
		qcom,lut-col-legend = <0xfffffff6 0x00 0x0a 0x19 0x28 0x32>;
		qcom,lut-row-legend = <0x2710 0x2648 0x2580 0x24b8 0x23f0 0x2328 0x2260 0x2198 0x20d0 0x2008 0x1f40 0x1e78 0x1db0 0x1ce8 0x1c20 0x1b58 0x1a90 0x19c8 0x1900 0x1838 0x1770 0x16a8 0x15e0 0x1518 0x1450 0x1388 0x12c0 0x11f8 0x1130 0x1068 0xfa0 0xed8 0xe10 0xd48 0xc80 0xbb8 0xaf0 0xa28 0x960 0x898 0x7d0 0x708 0x640 0x578 0x4b0 0x3e8 0x384 0x320 0x2bc 0x258 0x1f4 0x190 0x12c 0xc8 0x64 0x00>;
		qcom,lut-data = <0x4392 0x41a0 0x40ef 0x405d 0x403d 0x402f 0x43a9 0x41b9 0x4100 0x405d 0x403d 0x402f 0x43cd 0x41ea 0x4113 0x405d 0x403c 0x402f 0x43f4 0x4222 0x4125 0x405e 0x403c 0x4030 0x4412 0x4251 0x4133 0x405f 0x403c 0x4030 0x441f 0x4265 0x4138 0x4061 0x403d 0x4031 0x441c 0x4264 0x4136 0x4063 0x403f 0x4032 0x4417 0x4261 0x4131 0x4066 0x4042 0x4034 0x4420 0x4261 0x412f 0x406a 0x4043 0x4036 0x4461 0x4262 0x412f 0x406e 0x4043 0x4039 0x4491 0x4266 0x412f 0x4073 0x4044 0x403c 0x4419 0x429f 0x4134 0x4077 0x4048 0x403e 0x4332 0x42fe 0x413e 0x407b 0x404f 0x403f 0x42d2 0x4306 0x4151 0x4082 0x4055 0x4042 0x42b8 0x42a6 0x4179 0x408d 0x405c 0x4047 0x429d 0x424c 0x4191 0x4099 0x4064 0x404e 0x4262 0x422e 0x418f 0x40a7 0x406a 0x4055 0x4212 0x4218 0x4189 0x40b6 0x4071 0x405d 0x41cf 0x41f6 0x4178 0x40c2 0x407c 0x4066 0x4191 0x41be 0x413f 0x40cd 0x408c 0x4072 0x416c 0x4183 0x4106 0x40d3 0x4095 0x4079 0x4166 0x414b 0x40e1 0x40ac 0x4079 0x4065 0x4163 0x4119 0x40c3 0x406c 0x404d 0x4043 0x4163 0x4100 0x40b3 0x405a 0x4041 0x4039 0x4166 0x40f2 0x40a9 0x4056 0x403f 0x4036 0x416a 0x40ec 0x40a2 0x4055 0x403e 0x4035 0x416b 0x40ee 0x409c 0x4057 0x4040 0x4037 0x416d 0x40f5 0x4096 0x405c 0x4044 0x403a 0x416e 0x40fc 0x4090 0x4061 0x4048 0x403e 0x4171 0x4105 0x4086 0x4066 0x404e 0x4044 0x4175 0x410e 0x4081 0x406c 0x4055 0x404a 0x417a 0x4117 0x4081 0x4071 0x405e 0x4052 0x4180 0x4120 0x4082 0x4076 0x4066 0x4059 0x4184 0x4129 0x4089 0x4077 0x4067 0x405a 0x4188 0x4135 0x409a 0x4075 0x4066 0x4059 0x418b 0x413f 0x40af 0x4072 0x4063 0x4056 0x418b 0x4144 0x40c6 0x4069 0x4057 0x404e 0x418a 0x4148 0x40de 0x405e 0x4046 0x4041 0x418a 0x414b 0x40f2 0x405d 0x4043 0x403d 0x418a 0x414d 0x4103 0x405f 0x4044 0x403d 0x418a 0x4150 0x410e 0x4063 0x4044 0x403c 0x418e 0x4157 0x4110 0x4068 0x4043 0x403b 0x4198 0x4162 0x4112 0x406d 0x4042 0x403a 0x41a8 0x416b 0x4119 0x406f 0x403e 0x4034 0x41bf 0x4179 0x412a 0x4071 0x403d 0x4033 0x41c3 0x4181 0x4130 0x4070 0x4040 0x4039 0x41ae 0x418f 0x4146 0x4079 0x4048 0x403f 0x41c2 0x41b2 0x416d 0x408a 0x4054 0x4048 0x41da 0x41da 0x419c 0x40a2 0x405d 0x4056 0x421a 0x4209 0x41ce 0x40b7 0x4063 0x4059 0x42c2 0x4222 0x41eb 0x4098 0x4048 0x403a 0x43dc 0x423f 0x41ff 0x4094 0x4040 0x4037 0x4743 0x4322 0x422c 0x40ae 0x4046 0x403b 0x58b6 0x4756 0x42a6 0x40d4 0x4059 0x404a 0x58b6 0x4756 0x42a6 0x40d4 0x4059 0x404a 0x58b6 0x4756 0x42a6 0x40d4 0x4059 0x404a>;
	};

	qcom,pc-temp-y5-lut {
		qcom,lut-col-legend = <0xfffffff6 0x00 0x0a 0x19 0x28 0x32>;
		qcom,lut-row-legend = <0x2710 0x2648 0x2580 0x24b8 0x23f0 0x2328 0x2260 0x2198 0x20d0 0x2008 0x1f40 0x1e78 0x1db0 0x1ce8 0x1c20 0x1b58 0x1a90 0x19c8 0x1900 0x1838 0x1770 0x16a8 0x15e0 0x1518 0x1450 0x1388 0x12c0 0x11f8 0x1130 0x1068 0xfa0 0xed8 0xe10 0xd48 0xc80 0xbb8 0xaf0 0xa28 0x960 0x898 0x7d0 0x708 0x640 0x578 0x4b0 0x3e8 0x384 0x320 0x2bc 0x258 0x1f4 0x190 0x12c 0xc8 0x64 0x00>;
		qcom,lut-data = <0x2fe6 0x3bf6 0x4b94 0x57fb 0x44ea 0x5c47 0x30cf 0x3f29 0x4d61 0x55e6 0x45aa 0x591c 0x3252 0x4345 0x4efc 0x530f 0x45db 0x560e 0x33fc 0x475e 0x504a 0x4feb 0x459b 0x5338 0x355b 0x4a88 0x5131 0x4cee 0x450a 0x50b9 0x35fa 0x4bd7 0x5198 0x4a8a 0x4447 0x4eb0 0x35f2 0x4b95 0x517b 0x4879 0x42c7 0x4d3d 0x35da 0x4ada 0x510e 0x466b 0x4123 0x4bf5 0x37f7 0x48c4 0x5053 0x4491 0x41c4 0x49e7 0x4587 0x419e 0x4e6f 0x425e 0x469b 0x4683 0x4f85 0x3ccc 0x4bf8 0x413b 0x49c0 0x449d 0x49a4 0x436f 0x47fd 0x41db 0x479d 0x4773 0x3ece 0x4f44 0x43d8 0x42d7 0x4390 0x4bfe 0x3cab 0x5300 0x43ad 0x4289 0x409a 0x4c34 0x41a7 0x539c 0x478e 0x3fca 0x3df1 0x47e7 0x46d6 0x5446 0x4c6d 0x3df4 0x3cad 0x43bb 0x4987 0x5601 0x51ed 0x3eaf 0x3d78 0x4148 0x4b86 0x5854 0x5777 0x409d 0x3f6a 0x3f7f 0x4a8d 0x59e4 0x5a26 0x448e 0x4279 0x40ba 0x3e8a 0x5b1a 0x5bd3 0x4edd 0x4883 0x4981 0x3415 0x5bb5 0x5c92 0x575c 0x4e66 0x4f8c 0x3310 0x583e 0x5c85 0x5b19 0x5384 0x4f46 0x32a3 0x4fb6 0x5c64 0x5da3 0x57a7 0x4ecb 0x3264 0x46c3 0x5c87 0x5e03 0x56f6 0x4ef5 0x3233 0x3b32 0x5d55 0x5d56 0x4faa 0x5070 0x3219 0x33d2 0x5de0 0x5c76 0x4ae4 0x5174 0x325a 0x337b 0x5d6c 0x5b6b 0x4c8c 0x4f05 0x330e 0x33ac 0x5c71 0x5a7b 0x4f20 0x4aed 0x33ac 0x33e8 0x5a5c 0x5ac8 0x4f66 0x4a1f 0x3436 0x34a1 0x51d1 0x5d6a 0x4e4a 0x4af6 0x349f 0x3575 0x4b79 0x5f9a 0x4d9e 0x4c2f 0x34c3 0x3695 0x4afb 0x6027 0x4f64 0x4dd3 0x34c3 0x3851 0x4bad 0x608b 0x52eb 0x502b 0x34c9 0x3930 0x4d50 0x6164 0x5690 0x5369 0x34f3 0x3979 0x4f84 0x6330 0x5bae 0x58b9 0x3517 0x39b8 0x5168 0x6448 0x5ed7 0x5bd9 0x351e 0x3a41 0x52d1 0x63e4 0x5ebc 0x5bd6 0x3529 0x3afb 0x53e6 0x62f5 0x5db7 0x5bac 0x3527 0x3b2a 0x52fc 0x60fd 0x5c35 0x5a61 0x3498 0x3ad1 0x4be9 0x59f1 0x5902 0x53de 0x33d4 0x3a59 0x451b 0x5395 0x5669 0x4e8b 0x3352 0x39d3 0x4222 0x50a0 0x550b 0x4cd5 0x32f2 0x3916 0x3fe4 0x4f08 0x5403 0x4bdf 0x32f0 0x3877 0x3db5 0x4f8c 0x5150 0x50b2 0x3312 0x37b7 0x3baf 0x5165 0x4bbe 0x51bb 0x3490 0x37e8 0x3aae 0x5575 0x5491 0x4a9a 0x34dc 0x37d2 0x3b85 0x4ebb 0x4b8c 0x51e1 0x3562 0x3814 0x3cee 0x4fad 0x4604 0x519d 0x3675 0x3979 0x3cfa 0x4da0 0x5219 0x52f3 0x3567 0x3b09 0x3e8f 0x53cf 0x5439 0x5af6 0x31ff 0x3ac5 0x3e4b 0x50b7 0x52ce 0x51e3 0x2cd9 0x3659 0x3bc7 0x5321 0x5d88 0x5280 0x27ed 0x2ec3 0x370b 0x56a9 0x6066 0x5aa5 0x2469 0x27dc 0x3327 0x57e1 0x69f1 0x6d26 0x2469 0x27dc 0x3327 0x57e1 0x69f1 0x6d26 0x2469 0x27dc 0x3327 0x57e1 0x69f1 0x6d26>;
	};

	qcom,pc-temp-y6-lut {
		qcom,lut-col-legend = <0xfffffff6 0x00 0x0a 0x19 0x28 0x32>;
		qcom,lut-row-legend = <0x2710 0x2648 0x2580 0x24b8 0x23f0 0x2328 0x2260 0x2198 0x20d0 0x2008 0x1f40 0x1e78 0x1db0 0x1ce8 0x1c20 0x1b58 0x1a90 0x19c8 0x1900 0x1838 0x1770 0x16a8 0x15e0 0x1518 0x1450 0x1388 0x12c0 0x11f8 0x1130 0x1068 0xfa0 0xed8 0xe10 0xd48 0xc80 0xbb8 0xaf0 0xa28 0x960 0x898 0x7d0 0x708 0x640 0x578 0x4b0 0x3e8 0x384 0x320 0x2bc 0x258 0x1f4 0x190 0x12c 0xc8 0x64 0x00>;
		qcom,lut-data = <0x17a5 0x1521 0x141d 0x1380 0x135b 0x1355 0x179d 0x1537 0x1426 0x1380 0x135b 0x1355 0x1793 0x1547 0x142c 0x1380 0x135c 0x1355 0x1787 0x1551 0x142f 0x1380 0x135c 0x1355 0x177a 0x1557 0x1430 0x1380 0x135c 0x1356 0x176b 0x1559 0x1431 0x1381 0x135d 0x1356 0x1757 0x1555 0x142f 0x1381 0x135e 0x1357 0x1743 0x154e 0x142b 0x1382 0x135e 0x1357 0x1743 0x1545 0x1428 0x1383 0x1360 0x1358 0x1761 0x1538 0x1426 0x1384 0x1361 0x1359 0x1778 0x1531 0x1424 0x1385 0x1363 0x135a 0x1746 0x1542 0x1424 0x1387 0x1364 0x135b 0x16ea 0x155f 0x1424 0x1389 0x1365 0x135d 0x16cd 0x1562 0x1426 0x138c 0x1367 0x135e 0x16cb 0x1547 0x142f 0x138e 0x1368 0x1360 0x16c7 0x152d 0x1435 0x1391 0x136a 0x1361 0x16bd 0x1522 0x1434 0x1395 0x136d 0x1363 0x16ae 0x151a 0x1430 0x139b 0x1370 0x1365 0x169e 0x150e 0x1429 0x139f 0x1374 0x1368 0x168b 0x14fe 0x1415 0x13a2 0x137a 0x136d 0x167f 0x14ed 0x1402 0x13a3 0x137d 0x1371 0x1686 0x14dc 0x13f6 0x1396 0x1373 0x1368 0x169a 0x14cc 0x13ec 0x1381 0x1362 0x135a 0x16af 0x14c8 0x13e8 0x137b 0x135d 0x1357 0x16c6 0x14c8 0x13e6 0x1379 0x135c 0x1356 0x16de 0x14ca 0x13e5 0x1379 0x135b 0x1356 0x16f6 0x14d4 0x13e4 0x137a 0x135c 0x1356 0x170f 0x14ed 0x13e4 0x137c 0x135e 0x1357 0x1729 0x1506 0x13e3 0x137e 0x135f 0x1358 0x1743 0x151f 0x13df 0x1380 0x1361 0x135a 0x175e 0x153c 0x13de 0x1383 0x1363 0x135c 0x177b 0x155b 0x13e1 0x1385 0x1366 0x135f 0x179b 0x157e 0x13e9 0x1387 0x1369 0x1361 0x17b9 0x15a4 0x13f3 0x1387 0x136a 0x1362 0x17d5 0x15cf 0x1401 0x1387 0x136a 0x1361 0x17f0 0x15fc 0x1411 0x1386 0x1369 0x1361 0x1809 0x162c 0x1424 0x1385 0x1366 0x135e 0x1821 0x1660 0x143a 0x1382 0x1360 0x135a 0x1838 0x1696 0x144f 0x1382 0x1360 0x1359 0x184c 0x16ce 0x1465 0x1383 0x1360 0x1359 0x1860 0x1707 0x147c 0x1385 0x1360 0x1358 0x187b 0x173f 0x1495 0x1388 0x1360 0x1358 0x189c 0x1775 0x14b1 0x138c 0x1360 0x1358 0x18c4 0x17a7 0x14d4 0x138f 0x135e 0x1356 0x18fa 0x17d9 0x1502 0x1393 0x135e 0x1356 0x192e 0x17e0 0x1509 0x1394 0x1362 0x1359 0x1930 0x17e8 0x1520 0x1397 0x1364 0x135d 0x1985 0x1824 0x1549 0x13a0 0x1367 0x1361 0x19ea 0x186a 0x1575 0x13aa 0x136e 0x1366 0x1ac5 0x18ba 0x15ac 0x13b5 0x1370 0x1368 0x1cb8 0x1917 0x15e2 0x13aa 0x1366 0x135c 0x1ff9 0x19d7 0x1637 0x13ad 0x1366 0x135c 0x26dc 0x1c18 0x16d0 0x13be 0x1369 0x135f 0x38bb 0x21b6 0x1806 0x13d5 0x1372 0x1366 0x38bb 0x21b6 0x1806 0x13d5 0x1372 0x1366 0x38bb 0x21b6 0x1806 0x13d5 0x1372 0x1366>;
	};
};
